# ADSP-SC83xW_HPC register map
Vendor: Analog Devices; Series: ADSP-SC83xW_HPC; File version: 3.0.3.517
CPU: 
Registers are 32-bit, read-write, reset 0x0 unless marked. A register's access mark holds for its fields unless they carry their own. Offsets are from the block's base; [hi:lo] are bit positions; {n}, {i} and the like mark numbered series.

## CSETF0
Base 0x31109000
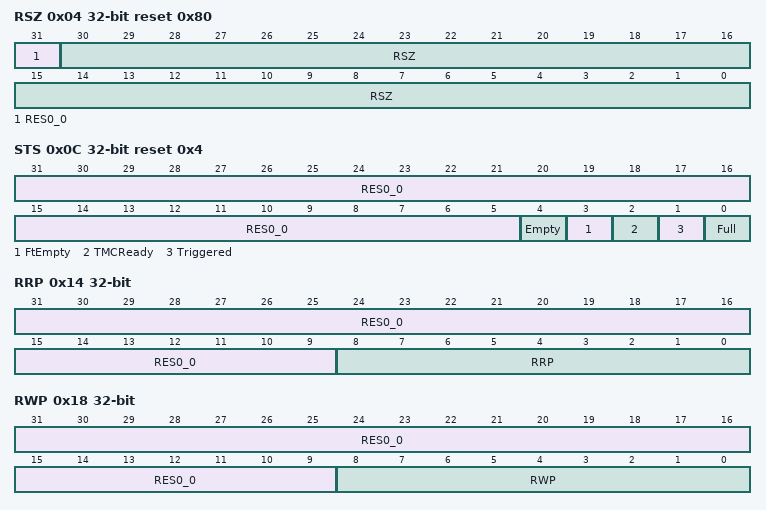
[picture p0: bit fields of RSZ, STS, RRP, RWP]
0x04 RSZ reset 0x80 — RAM Size register.
  [31] RES0_0 ro, [30:0] RSZ ro
0x0C STS reset 0x4 — Status register.
  [31:5] RES0_0 ro, [4] Empty ro, [3] FtEmpty ro, [2] TMCReady ro, [1] Triggered ro, [0] Full ro
0x10 RRD — RAM Read Data register.
  [31:0] RRD ro
0x14 RRP — RAM Read Pointer register.
  [31:9] RES0_0 range 0x00000000..0x007FFFFF, [8:0] RRP range 0x00000000..0x000001FF
0x18 RWP — RAM Write Pointer register.
  [31:9] RES0_0 range 0x00000000..0x007FFFFF, [8:0] RWP range 0x00000000..0x000001FF
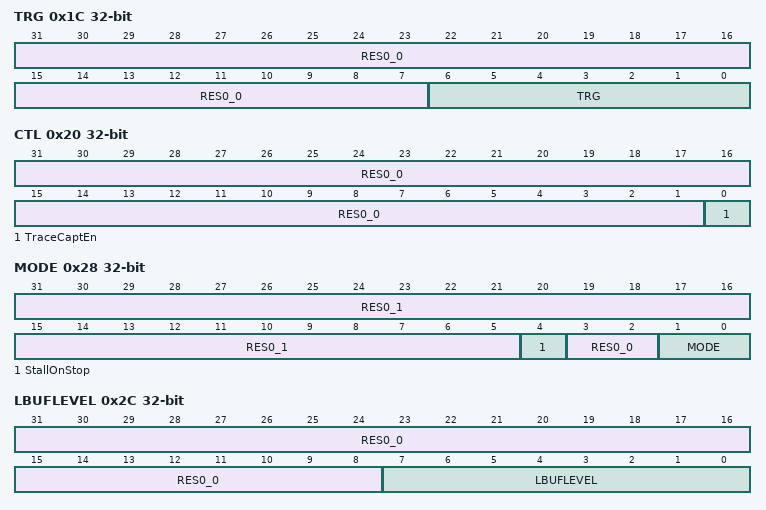
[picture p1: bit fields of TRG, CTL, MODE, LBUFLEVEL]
0x1C TRG — Trigger Counter register.
  [31:7] RES0_0 range 0x00000000..0x01FFFFFF, [6:0] TRG range 0x00000000..0x0000007F
0x20 CTL — Control Register.
  [31:1] RES0_0 range 0x00000000..0x7FFFFFFF, [0] TraceCaptEn range 0x00000000..0x00000001
0x24 RWD — RAM Write Data register.
  [31:0] RWD wo range 0x00000000..0xFFFFFFFF
0x28 MODE
  [31:5] RES0_1 range 0x00000000..0x07FFFFFF, [4] StallOnStop range 0x00000000..0x00000001, [3:2] RES0_0 range 0x00000000..0x00000003, [1:0] MODE range 0x00000000..0x00000003
0x2C LBUFLEVEL — Latched Buffer Fill Level.
  [31:8] RES0_0 ro, [7:0] LBUFLEVEL ro
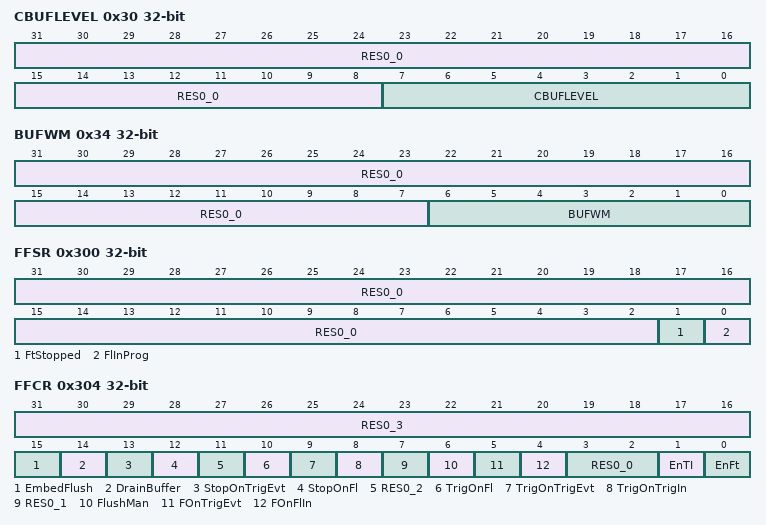
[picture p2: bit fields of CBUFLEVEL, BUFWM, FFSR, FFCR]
0x30 CBUFLEVEL — Current Buffer Fill Level.
  [31:8] RES0_0 ro, [7:0] CBUFLEVEL ro
0x34 BUFWM — Buffer Level Water Mark.
  [31:7] RES0_0 range 0x00000000..0x01FFFFFF, [6:0] BUFWM range 0x00000000..0x0000007F
0x300 FFSR — Formatter and Flush Status Register.
  [31:2] RES0_0 ro, [1] FtStopped ro, [0] FlInProg ro
0x304 FFCR — Formatter and Flush Control Register.
  [31:16] RES0_3 range 0x00000000..0x0000FFFF, [15] EmbedFlush range 0x00000000..0x00000001, [14] DrainBuffer wo range 0x00000000..0x00000001, [13] StopOnTrigEvt range 0x00000000..0x00000001, [12] StopOnFl range 0x00000000..0x00000001, [11] RES0_2 range 0x00000000..0x00000001, [10] TrigOnFl range 0x00000000..0x00000001, [9] TrigOnTrigEvt range 0x00000000..0x00000001, [8] TrigOnTrigIn range 0x00000000..0x00000001, [7] RES0_1 range 0x00000000..0x00000001, [6] FlushMan range 0x00000000..0x00000001, [5] FOnTrigEvt range 0x00000000..0x00000001, [4] FOnFlIn range 0x00000000..0x00000001, [3:2] RES0_0 range 0x00000000..0x00000003, [1] EnTI range 0x00000000..0x00000001, [0] EnFt range 0x00000000..0x00000001
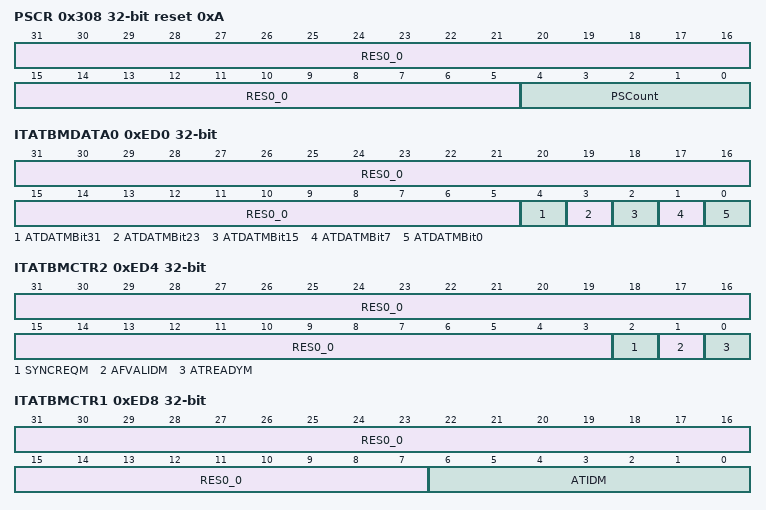
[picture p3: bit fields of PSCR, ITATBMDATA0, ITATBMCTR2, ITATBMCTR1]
0x308 PSCR reset 0xA — Periodic Synchronization Counter Register.
  [31:5] RES0_0 range 0x00000000..0x07FFFFFF, [4:0] PSCount range 0x00000000..0x0000001F
0xED0 ITATBMDATA0 — Integration Test ATB Master Data 0 register.
  [31:5] RES0_0 wo range 0x00000000..0x07FFFFFF, [4] ATDATMBit31 wo range 0x00000000..0x00000001, [3] ATDATMBit23 wo range 0x00000000..0x00000001, [2] ATDATMBit15 wo range 0x00000000..0x00000001, [1] ATDATMBit7 wo range 0x00000000..0x00000001, [0] ATDATMBit0 wo range 0x00000000..0x00000001
0xED4 ITATBMCTR2 — Integration Test ATB Master Control 2 register.
  [31:3] RES0_0 ro, [2] SYNCREQM ro, [1] AFVALIDM ro, [0] ATREADYM ro
0xED8 ITATBMCTR1 — Integration Test ATB Master Control 1 register.
  [31:7] RES0_0 wo range 0x00000000..0x01FFFFFF, [6:0] ATIDM wo range 0x00000000..0x0000007F
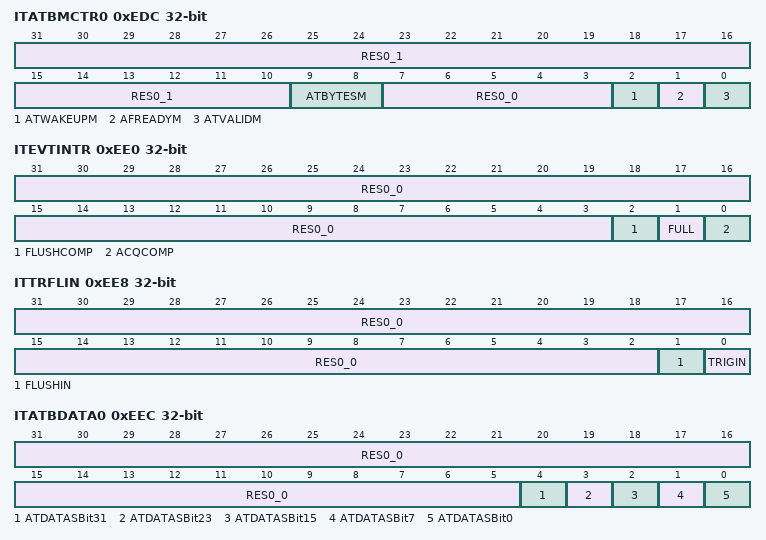
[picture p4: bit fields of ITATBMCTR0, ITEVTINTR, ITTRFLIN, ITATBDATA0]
0xEDC ITATBMCTR0 — Integration Test ATB Master Control 0 register.
  [31:10] RES0_1 wo range 0x00000000..0x003FFFFF, [9:8] ATBYTESM wo range 0x00000000..0x00000003, [7:3] RES0_0 wo range 0x00000000..0x0000001F, [2] ATWAKEUPM wo range 0x00000000..0x00000001, [1] AFREADYM wo range 0x00000000..0x00000001, [0] ATVALIDM wo range 0x00000000..0x00000001
0xEE0 ITEVTINTR — Integration Test Event and Interrupt Control Register.
  [31:3] RES0_0 wo range 0x00000000..0x1FFFFFFF, [2] FLUSHCOMP wo range 0x00000000..0x00000001, [1] FULL wo range 0x00000000..0x00000001, [0] ACQCOMP wo range 0x00000000..0x00000001
0xEE8 ITTRFLIN — Integration Test Trigger In and Flush In register.
  [31:2] RES0_0 ro, [1] FLUSHIN ro, [0] TRIGIN ro
0xEEC ITATBDATA0 — Integration Test ATB Data 0 Register.
  [31:5] RES0_0 ro, [4] ATDATASBit31 ro, [3] ATDATASBit23 ro, [2] ATDATASBit15 ro, [1] ATDATASBit7 ro, [0] ATDATASBit0 ro
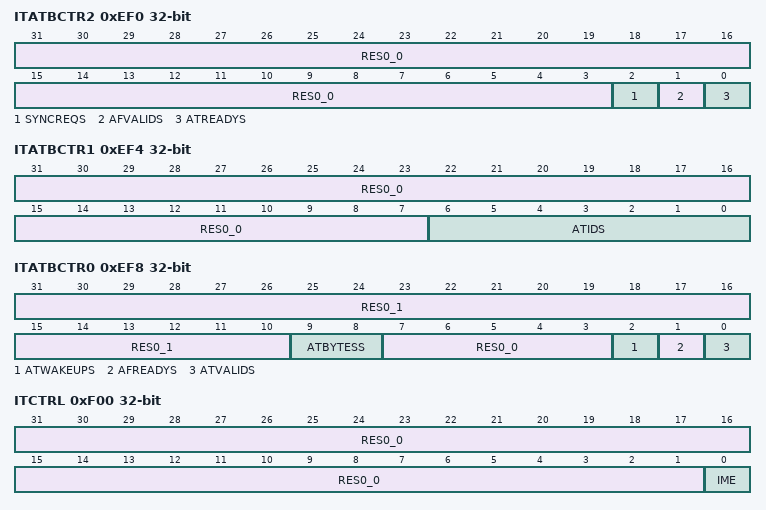
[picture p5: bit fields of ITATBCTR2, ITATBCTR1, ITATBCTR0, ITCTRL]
0xEF0 ITATBCTR2 — Integration Test ATB Control 2 Register.
  [31:3] RES0_0 wo range 0x00000000..0x1FFFFFFF, [2] SYNCREQS wo range 0x00000000..0x00000001, [1] AFVALIDS wo range 0x00000000..0x00000001, [0] ATREADYS wo range 0x00000000..0x00000001
0xEF4 ITATBCTR1 — Integration Test ATB Control 1 Register.
  [31:7] RES0_0 ro, [6:0] ATIDS ro
0xEF8 ITATBCTR0 — Integration Test ATB Control 0 Register.
  [31:10] RES0_1 ro, [9:8] ATBYTESS ro, [7:3] RES0_0 ro, [2] ATWAKEUPS ro, [1] AFREADYS ro, [0] ATVALIDS ro
0xF00 ITCTRL — Integration Mode Control Register.
  [31:1] RES0_0 range 0x00000000..0x7FFFFFFF, [0] IME range 0x00000000..0x00000001
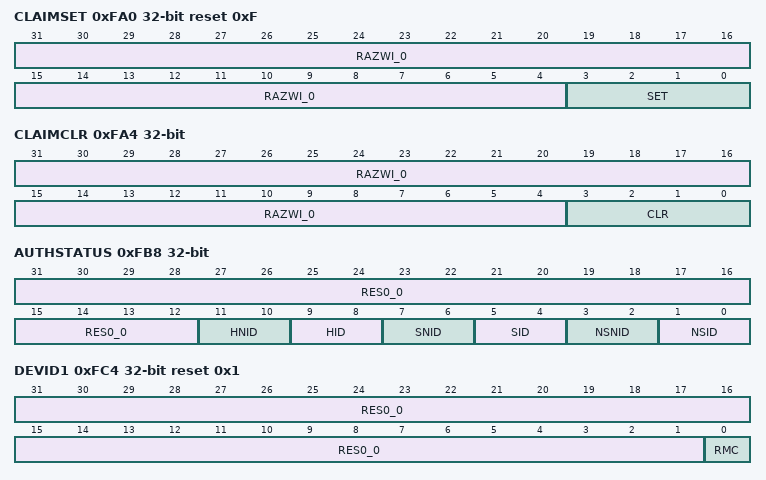
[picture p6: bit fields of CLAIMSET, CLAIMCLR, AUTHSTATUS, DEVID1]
0xFA0 CLAIMSET reset 0xF — Claim Tag Set Register.
  [31:4] RAZWI_0 range 0x00000000..0x0FFFFFFF, [3:0] SET range 0x00000000..0x0000000F
0xFA4 CLAIMCLR — Claim Tag Clear Register.
  [31:4] RAZWI_0 range 0x00000000..0x0FFFFFFF, [3:0] CLR range 0x00000000..0x0000000F
0xFB8 AUTHSTATUS — Authentication Status Register.
  [31:12] RES0_0 ro, [11:10] HNID ro, [9:8] HID ro, [7:6] SNID ro, [5:4] SID ro, [3:2] NSNID ro, [1:0] NSID ro
0xFC4 DEVID1 reset 0x1 — Device Configuration Register 1.
  [31:1] RES0_0 ro, [0] RMC ro
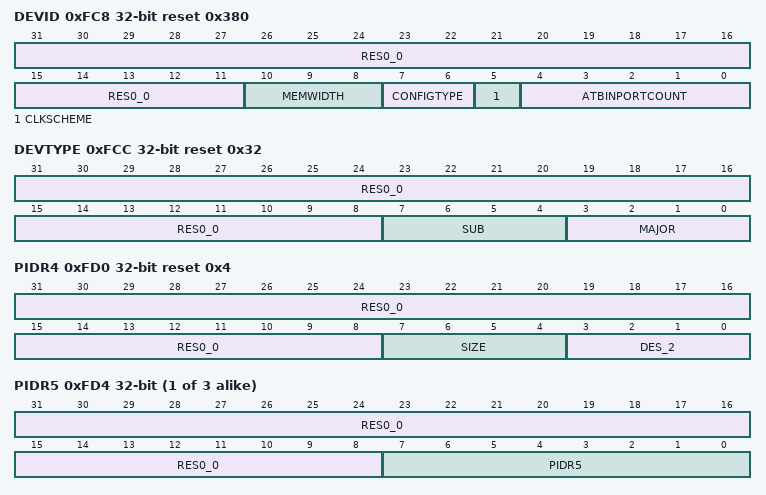
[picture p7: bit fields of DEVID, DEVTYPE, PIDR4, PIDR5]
0xFC8 DEVID reset 0x380 — Device Configuration Register.
  [31:11] RES0_0 ro, [10:8] MEMWIDTH ro, [7:6] CONFIGTYPE ro, [5] CLKSCHEME ro, [4:0] ATBINPORTCOUNT ro
0xFCC DEVTYPE reset 0x32 — Device Type Identifier Register.
  [31:8] RES0_0 ro, [7:4] SUB ro, [3:0] MAJOR ro
0xFD0 PIDR4 reset 0x4 — Peripheral Identification Register 4.
  [31:8] RES0_0 ro, [7:4] SIZE ro, [3:0] DES_2 ro
{0xFC0+4i} PIDR{i} (i=5..7) — Peripheral Identification Register {i}.
  [31:8] RES0_0 ro, [7:0] PIDR{i} ro
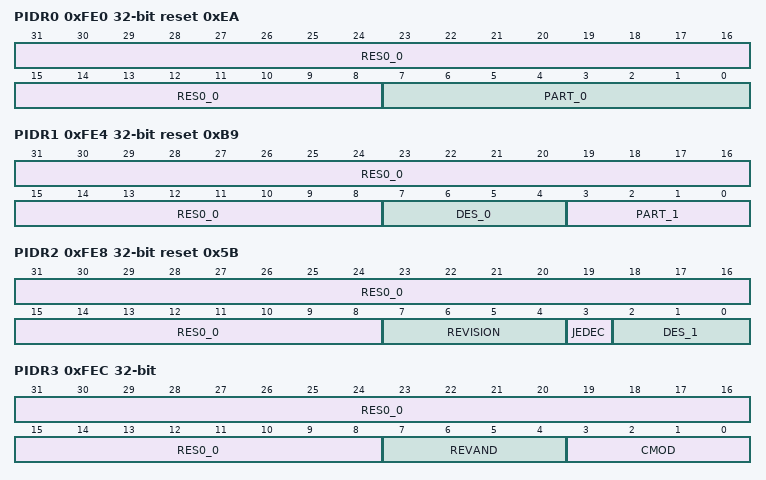
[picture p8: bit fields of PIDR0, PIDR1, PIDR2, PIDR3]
0xFE0 PIDR0 reset 0xEA — Peripheral Identification Register 0.
  [31:8] RES0_0 ro, [7:0] PART_0 ro
0xFE4 PIDR1 reset 0xB9 — Peripheral Identification Register 1.
  [31:8] RES0_0 ro, [7:4] DES_0 ro, [3:0] PART_1 ro
0xFE8 PIDR2 reset 0x5B — Peripheral Identification Register 2.
  [31:8] RES0_0 ro, [7:4] REVISION ro, [3] JEDEC ro, [2:0] DES_1 ro
0xFEC PIDR3 — Peripheral Identification Register 3.
  [31:8] RES0_0 ro, [7:4] REVAND ro, [3:0] CMOD ro
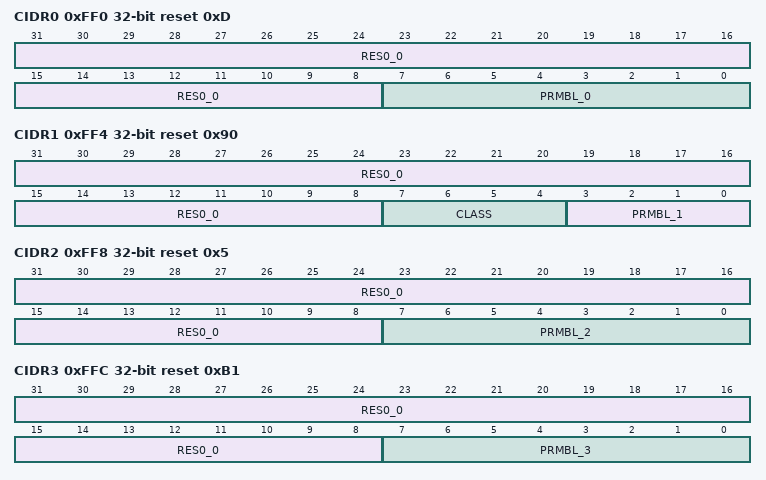
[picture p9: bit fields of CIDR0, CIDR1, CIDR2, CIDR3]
0xFF0 CIDR0 reset 0xD — Component Identification Register 0.
  [31:8] RES0_0 ro, [7:0] PRMBL_0 ro
0xFF4 CIDR1 reset 0x90 — Component Identification Register 1.
  [31:8] RES0_0 ro, [7:4] CLASS ro, [3:0] PRMBL_1 ro
0xFF8 CIDR2 reset 0x5 — Component Identification Register 2.
  [31:8] RES0_0 ro, [7:0] PRMBL_2 ro
0xFFC CIDR3 reset 0xB1 — Component Identification Register 3.
  [31:8] RES0_0 ro, [7:0] PRMBL_3 ro
